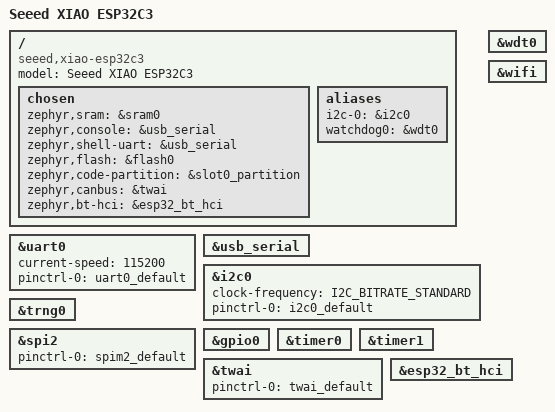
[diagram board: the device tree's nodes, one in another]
/*
 * Copyright 2022 Google LLC
 *
 * SPDX-License-Identifier: Apache-2.0
 */

/dts-v1/;

#include <espressif/esp32c3/esp32c3_fx4.dtsi>
#include "xiao_esp32c3-pinctrl.dtsi"
#include "seeed_xiao_connector.dtsi"
#include <espressif/partitions_0x0_default.dtsi>

/ {
	model = "Seeed XIAO ESP32C3";
	compatible = "seeed,xiao-esp32c3";

	chosen {
		zephyr,sram = &sram0;
		zephyr,console = &usb_serial;
		zephyr,shell-uart = &usb_serial;
		zephyr,flash = &flash0;
		zephyr,code-partition = &slot0_partition;
		zephyr,canbus = &twai;
		zephyr,bt-hci = &esp32_bt_hci;
	};

	aliases {
		i2c-0 = &i2c0;
		watchdog0 = &wdt0;
	};
};

&uart0 {
	status = "okay";
	current-speed = <115200>;
	pinctrl-0 = <&uart0_default>;
	pinctrl-names = "default";
};

&usb_serial {
	status = "okay";
};

&i2c0 {
	status = "okay";
	clock-frequency = <I2C_BITRATE_STANDARD>;
	pinctrl-0 = <&i2c0_default>;
	pinctrl-names = "default";
};

&trng0 {
	status = "okay";
};

&spi2 {
	#address-cells = <1>;
	#size-cells = <0>;
	status = "okay";
	pinctrl-0 = <&spim2_default>;
	pinctrl-names = "default";
};

&gpio0 {
	status = "okay";
};

&wdt0 {
	status = "okay";
};

&timer0 {
	status = "okay";
};

&timer1 {
	status = "okay";
};

&twai {
	status = "okay";
	pinctrl-0 = <&twai_default>;
	pinctrl-names = "default";
};

&wifi {
	status = "okay";
};

&esp32_bt_hci {
	status = "okay";
};
